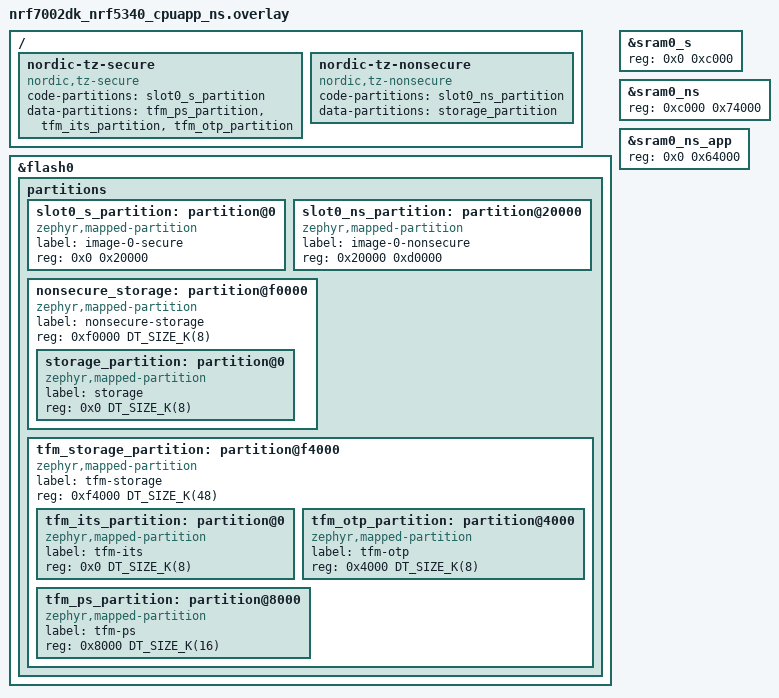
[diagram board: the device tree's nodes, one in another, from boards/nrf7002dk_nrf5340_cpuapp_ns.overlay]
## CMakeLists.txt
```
#
# Copyright (c) 2019 Nordic Semiconductor
#
# SPDX-License-Identifier: LicenseRef-Nordic-5-Clause
#

cmake_minimum_required(VERSION 3.20.0)

find_package(Zephyr REQUIRED HINTS $ENV{ZEPHYR_BASE})
project(coap-client)

if(CONFIG_COAP_SAMPLE_DTLS)
  set(gen_dir "${ZEPHYR_BINARY_DIR}/include/generated")

  generate_inc_file_for_target(
    app
    ${CONFIG_COAP_SAMPLE_CA_CERT_FILE}
    "${gen_dir}/coap_sample_ca_cert.inc"
  )

  generate_inc_file_for_target(
    app
    ${CONFIG_COAP_SAMPLE_CLIENT_CERT_FILE}
    "${gen_dir}/coap_sample_client_cert.inc"
  )

  generate_inc_file_for_target(
    app
    ${CONFIG_COAP_SAMPLE_CLIENT_KEY_FILE}
    "${gen_dir}/coap_sample_client_key.inc"
  )
endif()

# NORDIC SDK APP START
target_sources(app PRIVATE src/main.c)
# NORDIC SDK APP END
```

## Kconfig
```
#
# Copyright (c) 2019 Nordic Semiconductor ASA
#
# SPDX-License-Identifier: LicenseRef-Nordic-5-Clause
#

menu "CoAP client sample"

config COAP_SAMPLE_RESOURCE
	string "CoAP resource - defaults to Californium observable resource"
	default "obs"

config COAP_SAMPLE_SERVER_HOSTNAME
	string "CoAP server hostname"
	default "californium.eclipseprojects.io"

config COAP_SAMPLE_SERVER_PORT
	int "CoAP server port"
	default 5684 if COAP_SAMPLE_DTLS
	default 5683

config COAP_SAMPLE_REQUEST_INTERVAL_SECONDS
	int "Request interval in seconds"
	default 5

config SAMPLE_RECONNECT_DELAY_SECONDS
	int "Reconnect delay in seconds"
	default 30
	help
	  Delay before reconnecting to the server after a recoverable error,
	  such as a failed DTLS handshake or a failed request. A change in
	  network readiness ends the delay early.

config COAP_SAMPLE_DTLS
	bool "Enable DTLS (CoAPS) with mutual X.509 authentication"
	select NET_SOCKETS_SOCKOPT_TLS
	select NET_SOCKETS_ENABLE_DTLS
	select TLS_CREDENTIALS
	help
	  Enable DTLS for CoAP (CoAPS) using mutual X.509 certificate
	  authentication.  When enabled, the default server port changes to
	  5684 and the socket is created with IPPROTO_DTLS_1_2.

if COAP_SAMPLE_DTLS

config COAP_SAMPLE_DTLS_SEC_TAG
	int "DTLS security tag"
	default 42
	help
	  Security tag used to store the DTLS credentials.

config COAP_SAMPLE_DTLS_HANDSHAKE_TIMEOUT_MAX_MS
	int "Maximum DTLS handshake retransmission timeout in milliseconds"
	default 5000
	help
	  Caps the DTLS handshake retransmission backoff, to avoid blocking
	  for up to a minute.

config COAP_SAMPLE_CA_CERT_FILE
	string "CA certificate file (PEM)"
	default "cert/cf-ca.pem"
	help
	  Path to the CA certificate used to verify the server.
	  Relative to the sample root directory.

config COAP_SAMPLE_CLIENT_CERT_FILE
	string "Client certificate file (PEM)"
	default "cert/cf-client.pem"
	help
	  Path to the client certificate presented during mutual TLS.

config COAP_SAMPLE_CLIENT_KEY_FILE
	string "Client private key file (PEM)"
	default "cert/cf-client-key.pem"
	help
	  Path to the client private key.

endif # COAP_SAMPLE_DTLS

endmenu

menu "Zephyr Kernel"
source "Kconfig.zephyr"
endmenu

module = COAP_CLIENT_SAMPLE
module-str = CoAP client sample
source "$(ZEPHYR_BASE)/subsys/logging/Kconfig.template.log_config"
```

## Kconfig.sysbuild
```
#
# Copyright (c) 2024 Nordic Semiconductor ASA
#
# SPDX-License-Identifier: LicenseRef-Nordic-5-Clause
#

config WIFI_NRF70
	default y if BOARD_NRF7002DK_NRF5340_CPUAPP_NS || \
		BOARD_NRF54H20DK_NRF54H20_CPUAPP || \
		BOARD_NRF54LM20DK_NRF54LM20A_CPUAPP || \
		BOARD_NRF54LM20DK_NRF54LM20B_CPUAPP

source "share/sysbuild/Kconfig"
```

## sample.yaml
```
sample:
  name: CoAP client sample
tests:
  sample.net.coap_client:
    sysbuild: true
    build_only: true
    build_on_all: true
    integration_platforms:
      - nrf9151dk/nrf9151/ns
      - native_sim
    platform_allow:
      - nrf9151dk/nrf9151/ns
      - native_sim
    tags:
      - ci_build
      - sysbuild
      - ci_samples_net
  sample.net.coap_client.wifi:
    sysbuild: true
    build_only: true
    build_on_all: true
    integration_platforms:
      - nrf7002dk/nrf5340/cpuapp/ns
      - nrf7120dk/nrf7120/cpuapp/ns
    platform_allow:
      - nrf7002dk/nrf5340/cpuapp/ns
      - nrf7120dk/nrf7120/cpuapp/ns
    tags:
      - ci_build
      - sysbuild
      - ci_samples_net
    extra_args:
      - coap_client_EXTRA_CONF_FILE="wifi.conf"
  sample.net.coap_client.wifi.dtls:
    sysbuild: true
    build_only: true
    integration_platforms:
      - nrf7002dk/nrf5340/cpuapp/ns
      - nrf7120dk/nrf7120/cpuapp/ns
    platform_allow:
      - nrf7002dk/nrf5340/cpuapp/ns
      - nrf7120dk/nrf7120/cpuapp/ns
    tags:
      - ci_build
      - sysbuild
      - ci_samples_net
    extra_args:
      - coap_client_EXTRA_CONF_FILE="wifi.conf;wifi-dtls.conf"
  sample.net.coap_client.nrf54h20.wifi:
    sysbuild: true
    build_only: true
    integration_platforms:
      - nrf54h20dk/nrf54h20/cpuapp
    platform_allow:
      - nrf54h20dk/nrf54h20/cpuapp
    tags:
      - ci_build
      - sysbuild
      - ci_samples_net
    extra_args:
      - coap_client_SHIELD="nrf7002eb_interposer_p1;nrf7002eb"
      - coap_client_SNIPPET="nrf70-wifi;wifi-credentials"
      - coap_client_EXTRA_CONF_FILE=wifi.conf
  sample.net.coap_client.nrf54h20.wifi.dtls:
    sysbuild: true
    build_only: true
    integration_platforms:
      - nrf54h20dk/nrf54h20/cpuapp
    platform_allow:
      - nrf54h20dk/nrf54h20/cpuapp
    tags:
      - ci_build
      - sysbuild
      - ci_samples_net
    extra_args:
      - coap_client_SHIELD="nrf7002eb_interposer_p1;nrf7002eb"
      - coap_client_SNIPPET="nrf70-wifi;wifi-credentials"
      - coap_client_EXTRA_CONF_FILE="wifi.conf;wifi-dtls.conf"
  sample.net.coap_client.nrf54lm20_nrf7002eb2.wifi:
    sysbuild: true
    build_only: true
    integration_platforms:
      - nrf54lm20dk/nrf54lm20a/cpuapp
      - nrf54lm20dk/nrf54lm20b/cpuapp
    platform_allow:
      - nrf54lm20dk/nrf54lm20a/cpuapp
      - nrf54lm20dk/nrf54lm20b/cpuapp
    tags:
      - ci_build
      - sysbuild
      - ci_samples_net
    extra_args:
      - coap_client_SHIELD="nrf7002eb2"
      - coap_client_SNIPPET=wifi-credentials
      - coap_client_EXTRA_CONF_FILE=wifi.conf
  sample.net.coap_client.nrf54lm20_nrf7002eb2.wifi.dtls:
    sysbuild: true
    build_only: true
    integration_platforms:
      - nrf54lm20dk/nrf54lm20a/cpuapp
      - nrf54lm20dk/nrf54lm20b/cpuapp
    platform_allow:
      - nrf54lm20dk/nrf54lm20a/cpuapp
      - nrf54lm20dk/nrf54lm20b/cpuapp
    tags:
      - ci_build
      - sysbuild
      - ci_samples_net
    extra_args:
      - coap_client_SHIELD="nrf7002eb2"
      - coap_client_SNIPPET=wifi-credentials
      - coap_client_EXTRA_CONF_FILE="wifi.conf;wifi-dtls.conf"
```

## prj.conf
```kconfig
#
# Copyright (c) 2019 Nordic Semiconductor ASA
#
# SPDX-License-Identifier: LicenseRef-Nordic-5-Clause
#

# General
CONFIG_LOG=y
CONFIG_ASSERT=y
CONFIG_REBOOT=y
CONFIG_MAIN_STACK_SIZE=4096

# Networking
CONFIG_NETWORKING=y
CONFIG_NET_SOCKETS=y
CONFIG_POSIX_API=y
CONFIG_NET_NATIVE=y
CONFIG_NET_UDP=y
CONFIG_NET_IPV4=y
CONFIG_NET_CONNECTION_MANAGER=y
CONFIG_READY_RESOLVE=y

# CoAP
CONFIG_COAP=y
CONFIG_COAP_CLIENT=y
CONFIG_COAP_CLIENT_THREAD_PRIORITY=10
CONFIG_COAP_CLIENT_MESSAGE_SIZE=512
CONFIG_COAP_CLIENT_MESSAGE_HEADER_SIZE=64

# Needed for IPv6
CONFIG_COAP_CLIENT_STACK_SIZE=2048
```

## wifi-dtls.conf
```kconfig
#
# Copyright (c) 2026 Nordic Semiconductor ASA
#
# SPDX-License-Identifier: LicenseRef-Nordic-5-Clause
#

# Extra conf file that enables DTLS using mutual X.509 authentication.

# Enable DTLS
CONFIG_COAP_SAMPLE_DTLS=y
CONFIG_NET_SOCKETS_TLS_MAX_CONTEXTS=1

# mbedTLS
CONFIG_MBEDTLS=y
CONFIG_MBEDTLS_ENABLE_HEAP=y
CONFIG_MBEDTLS_HEAP_SIZE=80000
CONFIG_MBEDTLS_PEM_PARSE_C=y
CONFIG_MBEDTLS_SSL_KEEP_PEER_CERTIFICATE=n
CONFIG_MBEDTLS_SSL_SERVER_NAME_INDICATION=y
CONFIG_MBEDTLS_MPI_MAX_SIZE=512

# ECDHE-ECDSA ciphersuite matching the Californium server
CONFIG_MBEDTLS_CIPHERSUITE_TLS_ECDHE_ECDSA_WITH_AES_128_GCM_SHA256=y

# PSA crypto — ECDSA + ECDH over P-256 for the cert handshake
CONFIG_PSA_WANT_ALG_ECDSA=y
CONFIG_PSA_WANT_ALG_ECDH=y
CONFIG_PSA_WANT_ECC_SECP_R1_256=y

# Enable protected storage for credentials to be stored in flash
CONFIG_TLS_CREDENTIALS_BACKEND_PROTECTED_STORAGE=y

# Stack sizes
CONFIG_MAIN_STACK_SIZE=9000
CONFIG_COAP_CLIENT_STACK_SIZE=6144
```

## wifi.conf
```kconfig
#
# Copyright (c) 2026 Nordic Semiconductor ASA
#
# SPDX-License-Identifier: LicenseRef-Nordic-5-Clause
#

# Common Wi-Fi + networking configuration shared by all Wi-Fi builds of
# this sample (nRF70 and nRF71).

# Logging
CONFIG_NET_LOG=y

# Wi-Fi
CONFIG_WIFI=y
CONFIG_WIFI_NM_WPA_SUPPLICANT=y
CONFIG_NET_L2_ETHERNET=y

# Wi-Fi credentials. TF-M (_ns) builds use PSA Protected Storage. Non-TF-M
# builds use the Settings subsystem, requiring the wifi-credentials snippet.
CONFIG_WIFI_CREDENTIALS=y

# Zephyr NET Connection Manager Connectivity layer (sample drives connect).
CONFIG_L2_WIFI_CONNECTIVITY=y
CONFIG_L2_WIFI_CONNECTIVITY_AUTO_CONNECT=n
CONFIG_L2_WIFI_CONNECTIVITY_AUTO_DOWN=n

# Networking
CONFIG_NET_SOCKETS=y
CONFIG_NET_SOCKETS_OFFLOAD=n
CONFIG_NET_IPV6=y
CONFIG_NET_UDP=y
CONFIG_NET_TCP=y
CONFIG_NET_DHCPV4=y
# Run DHCPv6 on RA, covering both stateful and stateless configurations
CONFIG_NET_DHCPV6=y
CONFIG_NET_DHCPV6_START_ON_RA=y
CONFIG_NET_CONTEXT_SNDTIMEO=y
CONFIG_NET_CONTEXT_RCVTIMEO=y

# DNS
CONFIG_DNS_RESOLVER=y
CONFIG_NET_SOCKETS_DNS_TIMEOUT=30000

# Wi-Fi shell
CONFIG_SHELL=y
CONFIG_SHELL_CMDS_RESIZE=n
CONFIG_NET_L2_WIFI_SHELL=y

# Kernel options
CONFIG_POSIX_NETWORKING=y

# POSIX API memory optimizations
CONFIG_POSIX_FD_MGMT=n
CONFIG_POSIX_MESSAGE_PASSING=n
CONFIG_POSIX_THREAD_THREADS_MAX=0

# NET sockets
CONFIG_NET_MAX_CONN=8
CONFIG_NET_MAX_CONTEXTS=6
CONFIG_ZVFS_POLL_MAX=8

# NET buffers
CONFIG_NET_PKT_TX_COUNT=6
CONFIG_NET_PKT_RX_COUNT=6
CONFIG_NET_BUF_TX_COUNT=12
CONFIG_NET_BUF_RX_COUNT=6

# Stack sizes
CONFIG_NET_CONNECTION_MANAGER_MONITOR_STACK_SIZE=5000
CONFIG_MAIN_STACK_SIZE=6144
CONFIG_NET_TX_STACK_SIZE=4096
CONFIG_NET_RX_STACK_SIZE=4096
CONFIG_SYSTEM_WORKQUEUE_STACK_SIZE=4096
CONFIG_SHELL_STACK_SIZE=6144

# Heap sizes
CONFIG_HEAP_MEM_POOL_IGNORE_MIN=y
CONFIG_HEAP_MEM_POOL_SIZE=40144
CONFIG_NRF_WIFI_DATA_HEAP_SIZE=65536

# Floating-point printf support
CONFIG_CBPRINTF_FP_SUPPORT=y
```

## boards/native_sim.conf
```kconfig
#
# Copyright (c) 2024 Nordic Semiconductor ASA
#
# SPDX-License-Identifier: LicenseRef-Nordic-5-Clause
#

# Network address config
CONFIG_NET_CONFIG_SETTINGS=y
CONFIG_NET_IPV6=n
CONFIG_NET_CONFIG_NEED_IPV6=n
CONFIG_NET_CONFIG_NEED_IPV4=y
CONFIG_NET_CONFIG_MY_IPV4_ADDR="192.0.2.1"
CONFIG_NET_CONFIG_MY_IPV4_GW="192.0.2.2"

# DNS
CONFIG_DNS_RESOLVER=y
CONFIG_DNS_SERVER_IP_ADDRESSES=y
CONFIG_DNS_SERVER1="8.8.8.8"
```

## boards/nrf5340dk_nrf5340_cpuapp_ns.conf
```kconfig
#
# Copyright (c) 2025 Nordic Semiconductor ASA
#
# SPDX-License-Identifier: LicenseRef-Nordic-5-Clause
#

# General
CONFIG_POSIX_TIMERS=y
CONFIG_LOG_BUFFER_SIZE=4096
CONFIG_SYSTEM_WORKQUEUE_STACK_SIZE=4096
CONFIG_MAIN_STACK_SIZE=6144
CONFIG_HEAP_MEM_POOL_SIZE=40144
CONFIG_NRF_WIFI_CTRL_HEAP_SIZE=15000
CONFIG_NRF_WIFI_DATA_HEAP_SIZE=64856
CONFIG_HEAP_MEM_POOL_IGNORE_MIN=y

# Optimize TF-M
CONFIG_TFM_PROFILE_TYPE_SMALL=y

# Optimize Wi-Fi stack to save some memory
CONFIG_NRF70_RX_NUM_BUFS=16
CONFIG_NRF70_MAX_TX_AGGREGATION=4

# Wi-Fi
CONFIG_WIFI=y
CONFIG_WIFI_NRF70=y
CONFIG_WIFI_CREDENTIALS=y
CONFIG_NET_L2_WIFI_SHELL=y
CONFIG_FLASH=y
CONFIG_FLASH_PAGE_LAYOUT=y
CONFIG_FLASH_MAP=y
CONFIG_NVS=y
CONFIG_SETTINGS=y
CONFIG_SETTINGS_NVS=y

# Shell
CONFIG_SHELL=y
CONFIG_SHELL_STACK_SIZE=6144

# WPA
CONFIG_WIFI_NM_WPA_SUPPLICANT=y

# NET sockets
CONFIG_NET_L2_ETHERNET=y
CONFIG_NET_DHCPV4=y
CONFIG_NET_MGMT_EVENT_STACK_SIZE=4096
CONFIG_NET_RX_STACK_SIZE=4096

# DNS
CONFIG_DNS_RESOLVER=y
CONFIG_NET_SOCKETS_DNS_TIMEOUT=30000

# Zephyr NET Connection Manager Connectivity layer.
CONFIG_L2_WIFI_CONNECTIVITY=y
CONFIG_L2_WIFI_CONNECTIVITY_AUTO_DOWN=n
CONFIG_L2_WIFI_CONNECTIVITY_AUTO_CONNECT=n

# Floating-point printf support
CONFIG_CBPRINTF_FP_SUPPORT=y
```

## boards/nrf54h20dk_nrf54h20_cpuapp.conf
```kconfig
#
# Copyright (c) 2024 Nordic Semiconductor ASA
#
# SPDX-License-Identifier: LicenseRef-Nordic-5-Clause
#

# Logging
CONFIG_LOG=y
CONFIG_LOG_MODE_IMMEDIATE=y

# Wi-Fi
CONFIG_WIFI=y
CONFIG_WIFI_NRF70=y
CONFIG_WIFI_CREDENTIALS=y
# Needed for Wi-Fi credentials
CONFIG_FLASH=y
CONFIG_FLASH_PAGE_LAYOUT=y
CONFIG_FLASH_MAP=y
CONFIG_ZMS=y
CONFIG_SETTINGS=y

# WPA supplicant
CONFIG_WIFI_NM_WPA_SUPPLICANT=y
CONFIG_WIFI_NM_WPA_SUPPLICANT_LOG_LEVEL_INF=y

# Networking
CONFIG_NET_L2_ETHERNET=y
CONFIG_NET_SOCKETS=y
CONFIG_NET_IPV6=y
CONFIG_NET_UDP=y
CONFIG_NET_TCP=y
CONFIG_NET_DHCPV4=y
CONFIG_DNS_RESOLVER=y
CONFIG_DNS_RESOLVER_AI_MAX_ENTRIES=4

# NET sockets
CONFIG_NET_UDP=y
CONFIG_NET_TCP=y
CONFIG_NET_MAX_CONN=6
CONFIG_NET_MAX_CONTEXTS=5
CONFIG_ZVFS_POLL_MAX=8
CONFIG_NET_SOCKETS_OFFLOAD=n
CONFIG_NET_DHCPV4=y
CONFIG_NET_CONTEXT_SNDTIMEO=y
CONFIG_NET_CONTEXT_RCVTIMEO=y
CONFIG_NET_MAX_CONTEXTS=3

# NET buffers
CONFIG_NET_PKT_TX_COUNT=6
CONFIG_NET_PKT_RX_COUNT=6
CONFIG_NET_BUF_TX_COUNT=12
CONFIG_NET_BUF_RX_COUNT=6
CONFIG_NRF70_RX_NUM_BUFS=6
CONFIG_NET_PKT_BUF_RX_DATA_POOL_SIZE=4096
CONFIG_NET_PKT_BUF_TX_DATA_POOL_SIZE=4096
CONFIG_NRF70_MAX_TX_AGGREGATION=1

# Kernel options
CONFIG_POSIX_NETWORKING=y
CONFIG_ZVFS_OPEN_MAX=21

# Shell
CONFIG_SHELL=y
CONFIG_SHELL_CMDS_RESIZE=n
CONFIG_NET_L2_WIFI_SHELL=y

# Zephyr NET Connection Manager Connectivity layer.
CONFIG_L2_WIFI_CONNECTIVITY=y
CONFIG_L2_WIFI_CONNECTIVITY_AUTO_CONNECT=y
CONFIG_L2_WIFI_CONNECTIVITY_AUTO_DOWN=n

# Stack sizes
CONFIG_MAIN_STACK_SIZE=6144
CONFIG_NET_TX_STACK_SIZE=2048
CONFIG_NET_RX_STACK_SIZE=2048
CONFIG_NET_MGMT_EVENT_STACK_SIZE=4096
CONFIG_SYSTEM_WORKQUEUE_STACK_SIZE=3100
CONFIG_NRF70_IRQ_WQ_STACK_SIZE=1024
CONFIG_NRF70_BH_WQ_STACK_SIZE=2300
CONFIG_SHELL_STACK_SIZE=4400
CONFIG_ISR_STACK_SIZE=512

# Heap sizes
CONFIG_HEAP_MEM_POOL_IGNORE_MIN=y
CONFIG_HEAP_MEM_POOL_SIZE=32000
CONFIG_NRF_WIFI_CTRL_HEAP_SIZE=15000
CONFIG_NRF_WIFI_DATA_HEAP_SIZE=40000

# POSIX API memory optimizations
CONFIG_POSIX_FD_MGMT=n
CONFIG_POSIX_MESSAGE_PASSING=n
CONFIG_POSIX_THREAD_THREADS_MAX=0

# Floating-point printf support
CONFIG_CBPRINTF_FP_SUPPORT=y
```

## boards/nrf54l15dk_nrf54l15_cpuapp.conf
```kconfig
#
# Copyright (c) 2024 Nordic Semiconductor ASA
#
# SPDX-License-Identifier: LicenseRef-Nordic-5-Clause
#

# Logging
CONFIG_LOG=y
CONFIG_LOG_MODE_IMMEDIATE=y

# Wi-Fi
CONFIG_WIFI=y
CONFIG_WIFI_NRF70=y
CONFIG_WIFI_CREDENTIALS=y
# Needed for Wi-Fi credentials
CONFIG_FLASH=y
CONFIG_FLASH_PAGE_LAYOUT=y
CONFIG_FLASH_MAP=y
CONFIG_ZMS=y
CONFIG_SETTINGS=y

# WPA supplicant
CONFIG_WIFI_NM_WPA_SUPPLICANT=y
CONFIG_WIFI_NM_WPA_SUPPLICANT_LOG_LEVEL_INF=y

# Networking
CONFIG_NET_L2_ETHERNET=y
CONFIG_NET_SOCKETS=y
CONFIG_NET_IPV6=y
CONFIG_NET_UDP=y
CONFIG_NET_TCP=y
CONFIG_NET_DHCPV4=y
CONFIG_DNS_RESOLVER=y
CONFIG_DNS_RESOLVER_AI_MAX_ENTRIES=4

# NET sockets
CONFIG_NET_UDP=y
CONFIG_NET_TCP=y
CONFIG_NET_MAX_CONN=6
CONFIG_NET_MAX_CONTEXTS=5
CONFIG_ZVFS_POLL_MAX=8
CONFIG_NET_SOCKETS_OFFLOAD=n
CONFIG_NET_DHCPV4=y
CONFIG_NET_CONTEXT_SNDTIMEO=y
CONFIG_NET_CONTEXT_RCVTIMEO=y
CONFIG_NET_MAX_CONTEXTS=3

# NET buffers
CONFIG_NET_PKT_TX_COUNT=6
CONFIG_NET_PKT_RX_COUNT=6
CONFIG_NET_BUF_TX_COUNT=12
CONFIG_NET_BUF_RX_COUNT=6
CONFIG_NRF70_RX_NUM_BUFS=6
CONFIG_NET_PKT_BUF_RX_DATA_POOL_SIZE=4096
CONFIG_NET_PKT_BUF_TX_DATA_POOL_SIZE=4096
CONFIG_NRF70_MAX_TX_AGGREGATION=1

# Kernel options
CONFIG_POSIX_NETWORKING=y

# Shell
CONFIG_SHELL=y
CONFIG_SHELL_CMDS_RESIZE=n
CONFIG_NET_L2_WIFI_SHELL=y

# Zephyr NET Connection Manager Connectivity layer.
CONFIG_L2_WIFI_CONNECTIVITY=y
CONFIG_L2_WIFI_CONNECTIVITY_AUTO_CONNECT=y
CONFIG_L2_WIFI_CONNECTIVITY_AUTO_DOWN=n

# Stack sizes
CONFIG_MAIN_STACK_SIZE=6144
CONFIG_NET_TX_STACK_SIZE=2048
CONFIG_NET_RX_STACK_SIZE=2048
CONFIG_NET_MGMT_EVENT_STACK_SIZE=4096
CONFIG_SYSTEM_WORKQUEUE_STACK_SIZE=3100
CONFIG_NRF70_IRQ_WQ_STACK_SIZE=1024
CONFIG_NRF70_BH_WQ_STACK_SIZE=2300
CONFIG_SHELL_STACK_SIZE=4400
CONFIG_ISR_STACK_SIZE=512

# Heap sizes
CONFIG_HEAP_MEM_POOL_IGNORE_MIN=y
CONFIG_HEAP_MEM_POOL_SIZE=32000
CONFIG_NRF_WIFI_CTRL_HEAP_SIZE=15000
CONFIG_NRF_WIFI_DATA_HEAP_SIZE=40000

# POSIX API memory optimizations
CONFIG_POSIX_FD_MGMT=n
CONFIG_POSIX_MESSAGE_PASSING=n
CONFIG_POSIX_THREAD_THREADS_MAX=0

# Floating-point printf support
CONFIG_CBPRINTF_FP_SUPPORT=y
```

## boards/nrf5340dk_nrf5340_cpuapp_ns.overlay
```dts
/*
 * Copyright (c) 2026 Nordic Semiconductor ASA
 *
 * SPDX-License-Identifier: LicenseRef-Nordic-5-Clause
 */

/delete-node/ &boot_partition;
/delete-node/ &slot0_partition;
/delete-node/ &slot1_partition;
/delete-node/ &tfm_its_partition;
/delete-node/ &tfm_otp_partition;
/delete-node/ &tfm_ps_partition;
/delete-node/ &storage_partition;

&flash0 {
	partitions {
		slot0_s_partition: partition@0 {
			compatible = "zephyr,mapped-partition";
			label = "image-0-secure";
			reg = <0x0 0x20000>;
		};

		slot0_ns_partition: partition@20000 {
			compatible = "zephyr,mapped-partition";
			label = "image-0-nonsecure";
			reg = <0x20000 0xd0000>;
		};

		nonsecure_storage: partition@f0000 {
			compatible = "zephyr,mapped-partition";
			label = "nonsecure-storage";
			reg = <0xf0000 DT_SIZE_K(8)>;
			ranges = <0x0 0xf0000 DT_SIZE_K(8)>;
			#address-cells = <1>;
			#size-cells = <1>;

			storage_partition: partition@0 {
				compatible = "zephyr,mapped-partition";
				label = "storage";
				reg = <0x0 DT_SIZE_K(8)>;
			};
		};

		tfm_storage_partition: partition@f4000 {
			compatible = "zephyr,mapped-partition";
			label = "tfm-storage";
			reg = <0xf4000 DT_SIZE_K(48)>;
			ranges = <0x0 0xf4000 DT_SIZE_K(48)>;
			#address-cells = <1>;
			#size-cells = <1>;

			tfm_its_partition: partition@0 {
				compatible = "zephyr,mapped-partition";
				label = "tfm-its";
				reg = <0x0 DT_SIZE_K(8)>;
			};

			tfm_otp_partition: partition@4000 {
				compatible = "zephyr,mapped-partition";
				label = "tfm-otp";
				reg = <0x4000 DT_SIZE_K(8)>;
			};

			tfm_ps_partition: partition@8000 {
				compatible = "zephyr,mapped-partition";
				label = "tfm-ps";
				reg = <0x8000 DT_SIZE_K(16)>;
			};
		};
	};
};

/*
 * TrustZone SRAM split from devicetree (region_defs.h for TF-M). The secure image uses
 * 48 KiB (0xc000) at the base of cpuapp SRAM (&sram0_s); NS RAM begins at 0x20000000 + 0xc000.
 * &sram0_ns spans 0x74000 bytes; &sram0_ns_app is 0x64000 because the top 0x10000 (64 KiB)
 * within that NS window is sram0_shared for application/network-core IPC
 * (nrf5340_shared_sram_partition.dtsi), i.e. 0x64000 + 0x10000 == 0x74000.
 */
&sram0_s {
	reg = <0x0 0xc000>;
};

&sram0_ns {
	reg = <0xc000 0x74000>;
	ranges = <0x0 0xc000 0x74000>;
};

&sram0_ns_app {
	reg = <0x0 0x64000>;
};
```

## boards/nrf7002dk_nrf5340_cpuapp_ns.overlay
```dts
/*
 * Copyright (c) 2026 Nordic Semiconductor ASA
 *
 * SPDX-License-Identifier: LicenseRef-Nordic-5-Clause
 */

/delete-node/ &boot_partition;
/delete-node/ &slot0_partition;
/delete-node/ &slot1_partition;
/delete-node/ &tfm_its_partition;
/delete-node/ &tfm_otp_partition;
/delete-node/ &tfm_ps_partition;
/delete-node/ &storage_partition;

&flash0 {
	partitions {
		slot0_s_partition: partition@0 {
			compatible = "zephyr,mapped-partition";
			label = "image-0-secure";
			reg = <0x0 0x20000>;
		};

		slot0_ns_partition: partition@20000 {
			compatible = "zephyr,mapped-partition";
			label = "image-0-nonsecure";
			reg = <0x20000 0xd0000>;
		};

		nonsecure_storage: partition@f0000 {
			compatible = "zephyr,mapped-partition";
			label = "nonsecure-storage";
			reg = <0xf0000 DT_SIZE_K(8)>;
			ranges = <0x0 0xf0000 DT_SIZE_K(8)>;
			#address-cells = <1>;
			#size-cells = <1>;

			storage_partition: partition@0 {
				compatible = "zephyr,mapped-partition";
				label = "storage";
				reg = <0x0 DT_SIZE_K(8)>;
			};
		};

		tfm_storage_partition: partition@f4000 {
			compatible = "zephyr,mapped-partition";
			label = "tfm-storage";
			reg = <0xf4000 DT_SIZE_K(48)>;
			ranges = <0x0 0xf4000 DT_SIZE_K(48)>;
			#address-cells = <1>;
			#size-cells = <1>;

			tfm_its_partition: partition@0 {
				compatible = "zephyr,mapped-partition";
				label = "tfm-its";
				reg = <0x0 DT_SIZE_K(8)>;
			};

			tfm_otp_partition: partition@4000 {
				compatible = "zephyr,mapped-partition";
				label = "tfm-otp";
				reg = <0x4000 DT_SIZE_K(8)>;
			};

			tfm_ps_partition: partition@8000 {
				compatible = "zephyr,mapped-partition";
				label = "tfm-ps";
				reg = <0x8000 DT_SIZE_K(16)>;
			};
		};
	};
};

/*
 * TrustZone SRAM split from devicetree (region_defs.h for TF-M). The secure image uses
 * 48 KiB (0xc000) at the base of cpuapp SRAM (&sram0_s); NS RAM begins at 0x20000000 + 0xc000.
 * &sram0_ns spans 0x74000 bytes; &sram0_ns_app is 0x64000 because the top 0x10000 (64 KiB)
 * within that NS window is sram0_shared for application/network-core IPC
 * (nrf5340_shared_sram_partition.dtsi), i.e. 0x64000 + 0x10000 == 0x74000.
 */
&sram0_s {
	reg = <0x0 0xc000>;
};

&sram0_ns {
	reg = <0xc000 0x74000>;
	ranges = <0x0 0xc000 0x74000>;
};

&sram0_ns_app {
	reg = <0x0 0x64000>;
};

/ {
	/delete-node/ nordic-tz-secure;
	/delete-node/ nordic-tz-nonsecure;

	nordic-tz-secure {
		compatible = "nordic,tz-secure";
		code-partitions = <&slot0_s_partition>;
		data-partitions = <&tfm_ps_partition>,
				  <&tfm_its_partition>,
				  <&tfm_otp_partition>;
	};

	nordic-tz-nonsecure {
		compatible = "nordic,tz-nonsecure";
		code-partitions = <&slot0_ns_partition>;
		data-partitions = <&storage_partition>;
	};
};
```

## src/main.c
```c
/*
 * Copyright (c) 2019 Nordic Semiconductor ASA
 *
 * SPDX-License-Identifier: LicenseRef-Nordic-5-Clause
 */

#include <stdio.h>
#include <string.h>

#if defined(CONFIG_POSIX_API)
#include <zephyr/posix/arpa/inet.h>
#include <zephyr/posix/netdb.h>
#include <zephyr/posix/sys/socket.h>
#include <zephyr/posix/poll.h>
#else
#include <zephyr/net/socket.h>
#endif /* CONFIG_POSIX_API */

#include <zephyr/kernel.h>
#include <zephyr/sys/reboot.h>
#include <zephyr/net/coap.h>
#include <zephyr/net/socket.h>
#include <zephyr/net/conn_mgr_connectivity.h>
#include <zephyr/net/conn_mgr_monitor.h>
#include <zephyr/random/random.h>
#include <zephyr/net/coap_client.h>
#include <zephyr/logging/log.h>
#include <zephyr/logging/log_ctrl.h>
#include <zephyr/net/tls_credentials.h>

/* CONFIG_COAP_SAMPLE_DTLS_SEC_TAG and CONFIG_COAP_SAMPLE_DTLS_HANDSHAKE_TIMEOUT_MAX_MS
 * are defined in Kconfig under "if COAP_SAMPLE_DTLS", so they don't exist at all when
 * CONFIG_COAP_SAMPLE_DTLS is disabled. Provide fallback values so the code referencing
 * them below compiles unconditionally; the IS_ENABLED(CONFIG_COAP_SAMPLE_DTLS) runtime
 * check ensures they are never actually used in that case.
 */
#ifndef CONFIG_COAP_SAMPLE_DTLS_SEC_TAG
#define CONFIG_COAP_SAMPLE_DTLS_SEC_TAG 0
#endif
#ifndef CONFIG_COAP_SAMPLE_DTLS_HANDSHAKE_TIMEOUT_MAX_MS
#define CONFIG_COAP_SAMPLE_DTLS_HANDSHAKE_TIMEOUT_MAX_MS 0
#endif

LOG_MODULE_REGISTER(coap_client_sample, CONFIG_COAP_CLIENT_SAMPLE_LOG_LEVEL);

/* Macro used to subscribe to specific Zephyr NET management events. */
#define CONN_LAYER_EVENT_MASK (NET_EVENT_CONN_IF_FATAL_ERROR)

#define MAX_CONSECUTIVE_BUSY_RETRIES 5

/* Any IP family, and DNS to resolve the server host name */
#define READY_MASK (CONN_MGR_READY_IP_ANY | CONN_MGR_READY_DNS)

/* Macro called upon a fatal error, reboots the device. */
#define FATAL_ERROR()					\
	LOG_ERR("Fatal error! Rebooting the device.");	\
	LOG_PANIC();					\
	IF_ENABLED(CONFIG_REBOOT, (sys_reboot(0)))

static void server_addr_set_ipv4(struct sockaddr_storage *server, struct addrinfo *result)
{
	struct sockaddr_in *server4 = (struct sockaddr_in *)server;
	char addr_str[NET_IPV6_ADDR_LEN];

	server4->sin_addr.s_addr = ((struct sockaddr_in *)result->ai_addr)->sin_addr.s_addr;
	server4->sin_family = AF_INET;
	server4->sin_port = htons(CONFIG_COAP_SAMPLE_SERVER_PORT);

	inet_ntop(AF_INET, &server4->sin_addr.s_addr, addr_str, sizeof(addr_str));
	LOG_INF("IPv4 Address found %s", addr_str);
}

static void server_addr_set_ipv6(struct sockaddr_storage *server, struct addrinfo *result)
{
	struct sockaddr_in6 *server6 = (struct sockaddr_in6 *)server;
	char addr_str[NET_IPV6_ADDR_LEN];

	memcpy(&server6->sin6_addr,
	       &((struct sockaddr_in6 *)result->ai_addr)->sin6_addr,
	       sizeof(server6->sin6_addr));
	server6->sin6_family = AF_INET6;
	server6->sin6_port = htons(CONFIG_COAP_SAMPLE_SERVER_PORT);

	inet_ntop(AF_INET6, &server6->sin6_addr, addr_str, sizeof(addr_str));
	LOG_INF("IPv6 Address found %s", addr_str);
}

/* Resolves the server for the address families that are ready */
static int server_resolve(struct addrinfo **result)
{
	int err;
	struct addrinfo hints = {
		.ai_family = conn_mgr_get_ready_addr_family(),
		.ai_socktype = SOCK_DGRAM
	};

	err = getaddrinfo(CONFIG_COAP_SAMPLE_SERVER_HOSTNAME, NULL, &hints, result);
	if (err) {
		LOG_ERR("getaddrinfo, error: %d", err);
		return err;
	}

	return 0;
}

static int server_addr_set(struct sockaddr_storage *server, struct addrinfo *result)
{
	/* Resolve either IPv4 or IPv6 */
	switch (result->ai_family) {
	case AF_INET:
		server_addr_set_ipv4(server, result);
		return 0;
	case AF_INET6:
		if (IS_ENABLED(CONFIG_NET_IPV6)) {
			server_addr_set_ipv6(server, result);
			return 0;
		}
		__fallthrough;
	default:
		LOG_ERR("Unexpected address family: %d", result->ai_family);
		return -EAFNOSUPPORT;
	}
}

static void response_cb(const struct coap_client_response_data *data, void *user_data)
{
	if (data->result_code >= 0) {
		LOG_INF("CoAP response: code: 0x%x, payload: %s",
			data->result_code, data->payload);
	} else {
		LOG_INF("Response received with error code: %d", data->result_code);
	}
}

static int credentials_add(void)
{
	int err;

	if (IS_ENABLED(CONFIG_COAP_SAMPLE_DTLS)) {
		static const char ca_cert[] = {
#if defined(CONFIG_COAP_SAMPLE_DTLS)
			#include "coap_sample_ca_cert.inc"
			'\0'
#endif
		};
		static const char client_cert[] = {
#if defined(CONFIG_COAP_SAMPLE_DTLS)
			#include "coap_sample_client_cert.inc"
			'\0'
#endif
		};
		static const char client_key[] = {
#if defined(CONFIG_COAP_SAMPLE_DTLS)
			#include "coap_sample_client_key.inc"
			'\0'
#endif
		};

		err = tls_credential_add(CONFIG_COAP_SAMPLE_DTLS_SEC_TAG,
					 TLS_CREDENTIAL_CA_CERTIFICATE,
					 ca_cert, sizeof(ca_cert));
		if ((err < 0) && (err != -EEXIST)) {
			LOG_ERR("Failed to register CA certificate: %d", err);
			FATAL_ERROR();
			return err;
		}

		err = tls_credential_add(CONFIG_COAP_SAMPLE_DTLS_SEC_TAG,
					 TLS_CREDENTIAL_PUBLIC_CERTIFICATE,
					 client_cert, sizeof(client_cert));
		if ((err < 0) && (err != -EEXIST)) {
			LOG_ERR("Failed to register client certificate: %d", err);
			FATAL_ERROR();
			return err;
		}

		err = tls_credential_add(CONFIG_COAP_SAMPLE_DTLS_SEC_TAG,
					 TLS_CREDENTIAL_PRIVATE_KEY,
					 client_key, sizeof(client_key));
		if ((err < 0) && (err != -EEXIST)) {
			LOG_ERR("Failed to register private key: %d", err);
			FATAL_ERROR();
			return err;
		}
	}

	return 0;
}

/* Opens a socket to the server, performing the DTLS handshake if enabled.
 * Returns the socket on success, or a negative error code on a recoverable failure.
 */
static int server_connect(struct sockaddr_storage *server)
{
	int err, sock;

	sock = socket(server->ss_family, SOCK_DGRAM,
		      IS_ENABLED(CONFIG_COAP_SAMPLE_DTLS) ? IPPROTO_DTLS_1_2 : IPPROTO_UDP);
	if (sock < 0) {
		LOG_ERR("Failed to create CoAP socket: %d.", -errno);
		FATAL_ERROR();
		return -errno;
	}

	if (IS_ENABLED(CONFIG_COAP_SAMPLE_DTLS)) {
		sec_tag_t sec_tag_list[] = { CONFIG_COAP_SAMPLE_DTLS_SEC_TAG };

		err = setsockopt(sock, SOL_TLS, TLS_SEC_TAG_LIST,
				 sec_tag_list, sizeof(sec_tag_list));
		if (err < 0) {
			LOG_ERR("Failed to set TLS_SEC_TAG_LIST: %d", -errno);
			(void)zsock_close(sock);
			FATAL_ERROR();
			return -errno;
		}

		uint32_t handshake_timeout_ms = CONFIG_COAP_SAMPLE_DTLS_HANDSHAKE_TIMEOUT_MAX_MS;

		err = setsockopt(sock, SOL_TLS, TLS_DTLS_HANDSHAKE_TIMEOUT_MAX,
				 &handshake_timeout_ms, sizeof(handshake_timeout_ms));
		if (err < 0) {
			LOG_ERR("Failed to set TLS_DTLS_HANDSHAKE_TIMEOUT_MAX: %d", -errno);
			(void)zsock_close(sock);
			FATAL_ERROR();
			return -errno;
		}

		/* Set the expected server hostname for SNI and server certificate
		 * CN/SAN verification.
		 */
		err = setsockopt(sock, SOL_TLS, TLS_HOSTNAME,
				 CONFIG_COAP_SAMPLE_SERVER_HOSTNAME,
				 sizeof(CONFIG_COAP_SAMPLE_SERVER_HOSTNAME) - 1);
		if (err < 0) {
			LOG_ERR("Failed to set TLS_HOSTNAME: %d", -errno);
			(void)zsock_close(sock);
			FATAL_ERROR();
			return -errno;
		}

		/* Explicitly connect to trigger the DTLS handshake now so we can log
		 * the outcome and negotiated ciphersuite before handing the socket to
		 * the CoAP client.
		 */
		LOG_INF("Performing DTLS handshake with %s:%d (mutual TLS)...",
			CONFIG_COAP_SAMPLE_SERVER_HOSTNAME,
			CONFIG_COAP_SAMPLE_SERVER_PORT);

		err = zsock_connect(sock, (struct sockaddr *)server,
				    server->ss_family == AF_INET6 ?
					    sizeof(struct sockaddr_in6) :
					    sizeof(struct sockaddr_in));
		if (err < 0) {
			err = -errno;
			LOG_ERR("DTLS handshake failed: %d", err);
			(void)zsock_close(sock);
			return err;
		}

		int cipher_id;
		socklen_t cipher_id_len = sizeof(cipher_id);

		err = getsockopt(sock, SOL_TLS, TLS_CIPHERSUITE_USED, &cipher_id, &cipher_id_len);
		if (err == 0) {
			LOG_INF("DTLS handshake complete, ciphersuite: 0x%04x", cipher_id);
		} else {
			LOG_INF("DTLS handshake complete (ciphersuite unknown, getsockopt err %d)",
				-errno);
		}
	}

	return sock;
}

/* Resolves the server and connects to the first address that accepts a connection */
static int server_resolve_and_connect(struct sockaddr_storage *server)
{
	struct addrinfo *result;
	struct addrinfo *ai;
	int sock = -ENOENT;
	int err;

	err = server_resolve(&result);
	if (err) {
		LOG_ERR("Failed to resolve server name");
		return err;
	}

	for (ai = result; ai != NULL && sock < 0; ai = ai->ai_next) {
		if (server_addr_set(server, ai) == 0) {
			sock = server_connect(server);
		}
	}

	freeaddrinfo(result);

	return sock;
}

static void server_disconnect(struct coap_client *coap_client, int *sock)
{
	coap_client_cancel_requests(coap_client);
	(void)zsock_close(*sock);
	*sock = -1;
}

/* Only returns on fatal errors. Recoverable errors close the socket and reconnect. */
static int periodic_coap_request_loop(void)
{
	int err;
	int sock = -1;
	int consecutive_busy_retries = 0;
	uint32_t last_seen = 0;
	struct sockaddr_storage server = { 0 };
	struct coap_client coap_client = { 0 };
	struct coap_client_request req = {
		.method = COAP_METHOD_GET,
		.confirmable = true,
		.fmt = COAP_CONTENT_FORMAT_TEXT_PLAIN,
		.payload = NULL,
		.cb = response_cb,
		.len = 0,
		.path = CONFIG_COAP_SAMPLE_RESOURCE,
	};

	err = credentials_add();
	if (err) {
		return err;
	}

	err = coap_client_init(&coap_client, NULL);
	if (err) {
		LOG_ERR("Failed to initialize CoAP client: %d", err);
		FATAL_ERROR();
		return err;
	}

	LOG_INF("Waiting for network...");
	(void)conn_mgr_wait_ready(READY_MASK, NULL, K_FOREVER);
	LOG_INF("Network ready");

	while (true) {
		if (sock < 0) {
			/* At once the first time, then after the delay or a network change */
			err = conn_mgr_wait_ready(READY_MASK, &last_seen,
						  K_SECONDS(CONFIG_SAMPLE_RECONNECT_DELAY_SECONDS));
			if (err == -EAGAIN) {
				/* The network is not ready. Keep waiting. */
				continue;
			} else if (err != 0) {
				return err;
			}

			sock = server_resolve_and_connect(&server);
			if (sock < 0) {
				LOG_WRN("Failed to connect to server: %d, retrying in %d seconds",
					sock, CONFIG_SAMPLE_RECONNECT_DELAY_SECONDS);
				continue;
			}
		}

		/* Send request */
		err = coap_client_req(&coap_client, sock, (struct sockaddr *)&server, &req, NULL);
		if (err == -EAGAIN &&
		    ++consecutive_busy_retries < MAX_CONSECUTIVE_BUSY_RETRIES) {
			LOG_WRN("CoAP client busy, retrying later");
			k_sleep(K_SECONDS(CONFIG_COAP_SAMPLE_REQUEST_INTERVAL_SECONDS));
			continue;
		}

		consecutive_busy_retries = 0;

		if (err) {
			LOG_ERR("Failed to send request: %d, reconnecting", err);
			server_disconnect(&coap_client, &sock);
			continue;
		}

		LOG_INF("CoAP GET request sent to %s:%d, resource: %s",
			CONFIG_COAP_SAMPLE_SERVER_HOSTNAME,
			CONFIG_COAP_SAMPLE_SERVER_PORT,
			CONFIG_COAP_SAMPLE_RESOURCE);

		k_sleep(K_SECONDS(CONFIG_COAP_SAMPLE_REQUEST_INTERVAL_SECONDS));
	}
}

static void connectivity_event_handler(uint64_t event, struct net_if *iface, void *info,
				       size_t info_length, void *user_data)
{
	if (event == NET_EVENT_CONN_IF_FATAL_ERROR) {
		LOG_ERR("NET_EVENT_CONN_IF_FATAL_ERROR");
		FATAL_ERROR();
		return;
	}
}

/* Registered statically to not miss events raised before main() */
NET_MGMT_REGISTER_EVENT_HANDLER(conn_events, CONN_LAYER_EVENT_MASK, connectivity_event_handler,
				NULL);

int main(void)
{
	int err;

	LOG_INF("The CoAP client sample started");

	/* Bring all network interfaces up.
	 * Wi-Fi or LTE depending on the board that the sample was built for.
	 */
	LOG_INF("Bringing network interface up and connecting to the network");

	err = conn_mgr_all_if_up(true);
	if (err) {
		LOG_ERR("conn_mgr_all_if_up, error: %d", err);
		FATAL_ERROR();
		return err;
	}

	err = conn_mgr_all_if_connect(true);
	if (err) {
		LOG_ERR("conn_mgr_all_if_connect, error: %d", err);
		FATAL_ERROR();
		return err;
	}

	err = periodic_coap_request_loop();
	if (err) {
		LOG_ERR("periodic_coap_request_loop, error: %d", err);
	}

	LOG_INF("Bringing network interfaces down");
	(void)conn_mgr_all_if_disconnect(true);
	(void)conn_mgr_all_if_down(true);

	return err;
}
```
